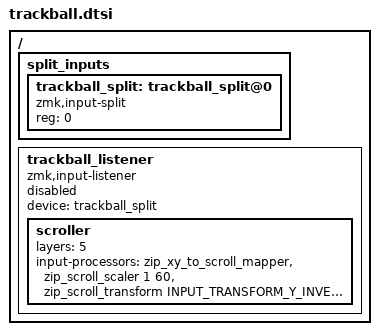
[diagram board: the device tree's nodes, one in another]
#include <input/processors.dtsi>
#include <dt-bindings/zmk/input_transform.h>

 / {
    split_inputs {
        #address-cells = <1>;
        #size-cells = <0>;

        trackball_split: trackball_split@0 {
            compatible = "zmk,input-split";
            reg = <0>;
        };
    };

    trackball_listener: trackball_listener {
        compatible = "zmk,input-listener";
        status = "disabled";
        device = <&trackball_split>;

        scroller {
            layers = <5>;
            input-processors =
                <&zip_xy_to_scroll_mapper &zip_scroll_scaler 1 60>,
                <&zip_scroll_transform INPUT_TRANSFORM_Y_INVERT>;
        };
    };
};
